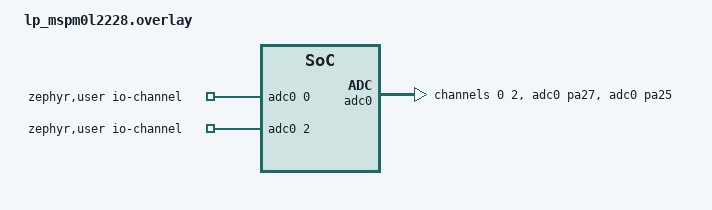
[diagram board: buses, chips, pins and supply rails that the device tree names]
/*
 * SPDX-License-Identifier: Apache-2.0
 */

#include <zephyr/dt-bindings/adc/adc.h>

/ {
	zephyr,user {
		io-channels = <&adc0 0>, <&adc0 2>;
	};
};

&adc0 {
	status = "okay";
	pinctrl-0 = <&adc0_pa27 &adc0_pa25>;

	#address-cells = <1>;
	#size-cells = <0>;

	channel@0 {
		reg = <0>;
		zephyr,gain = "ADC_GAIN_1";
		zephyr,reference = "ADC_REF_INTERNAL";
		zephyr,acquisition-time = <ADC_ACQ_TIME(ADC_ACQ_TIME_TICKS, 500)>;
		zephyr,resolution = <12>;
	};

	channel@2 {
		reg = <2>;
		zephyr,gain = "ADC_GAIN_1";
		zephyr,reference = "ADC_REF_INTERNAL";
		zephyr,acquisition-time = <ADC_ACQ_TIME(ADC_ACQ_TIME_TICKS, 500)>;
		zephyr,resolution = <12>;
	};

};
